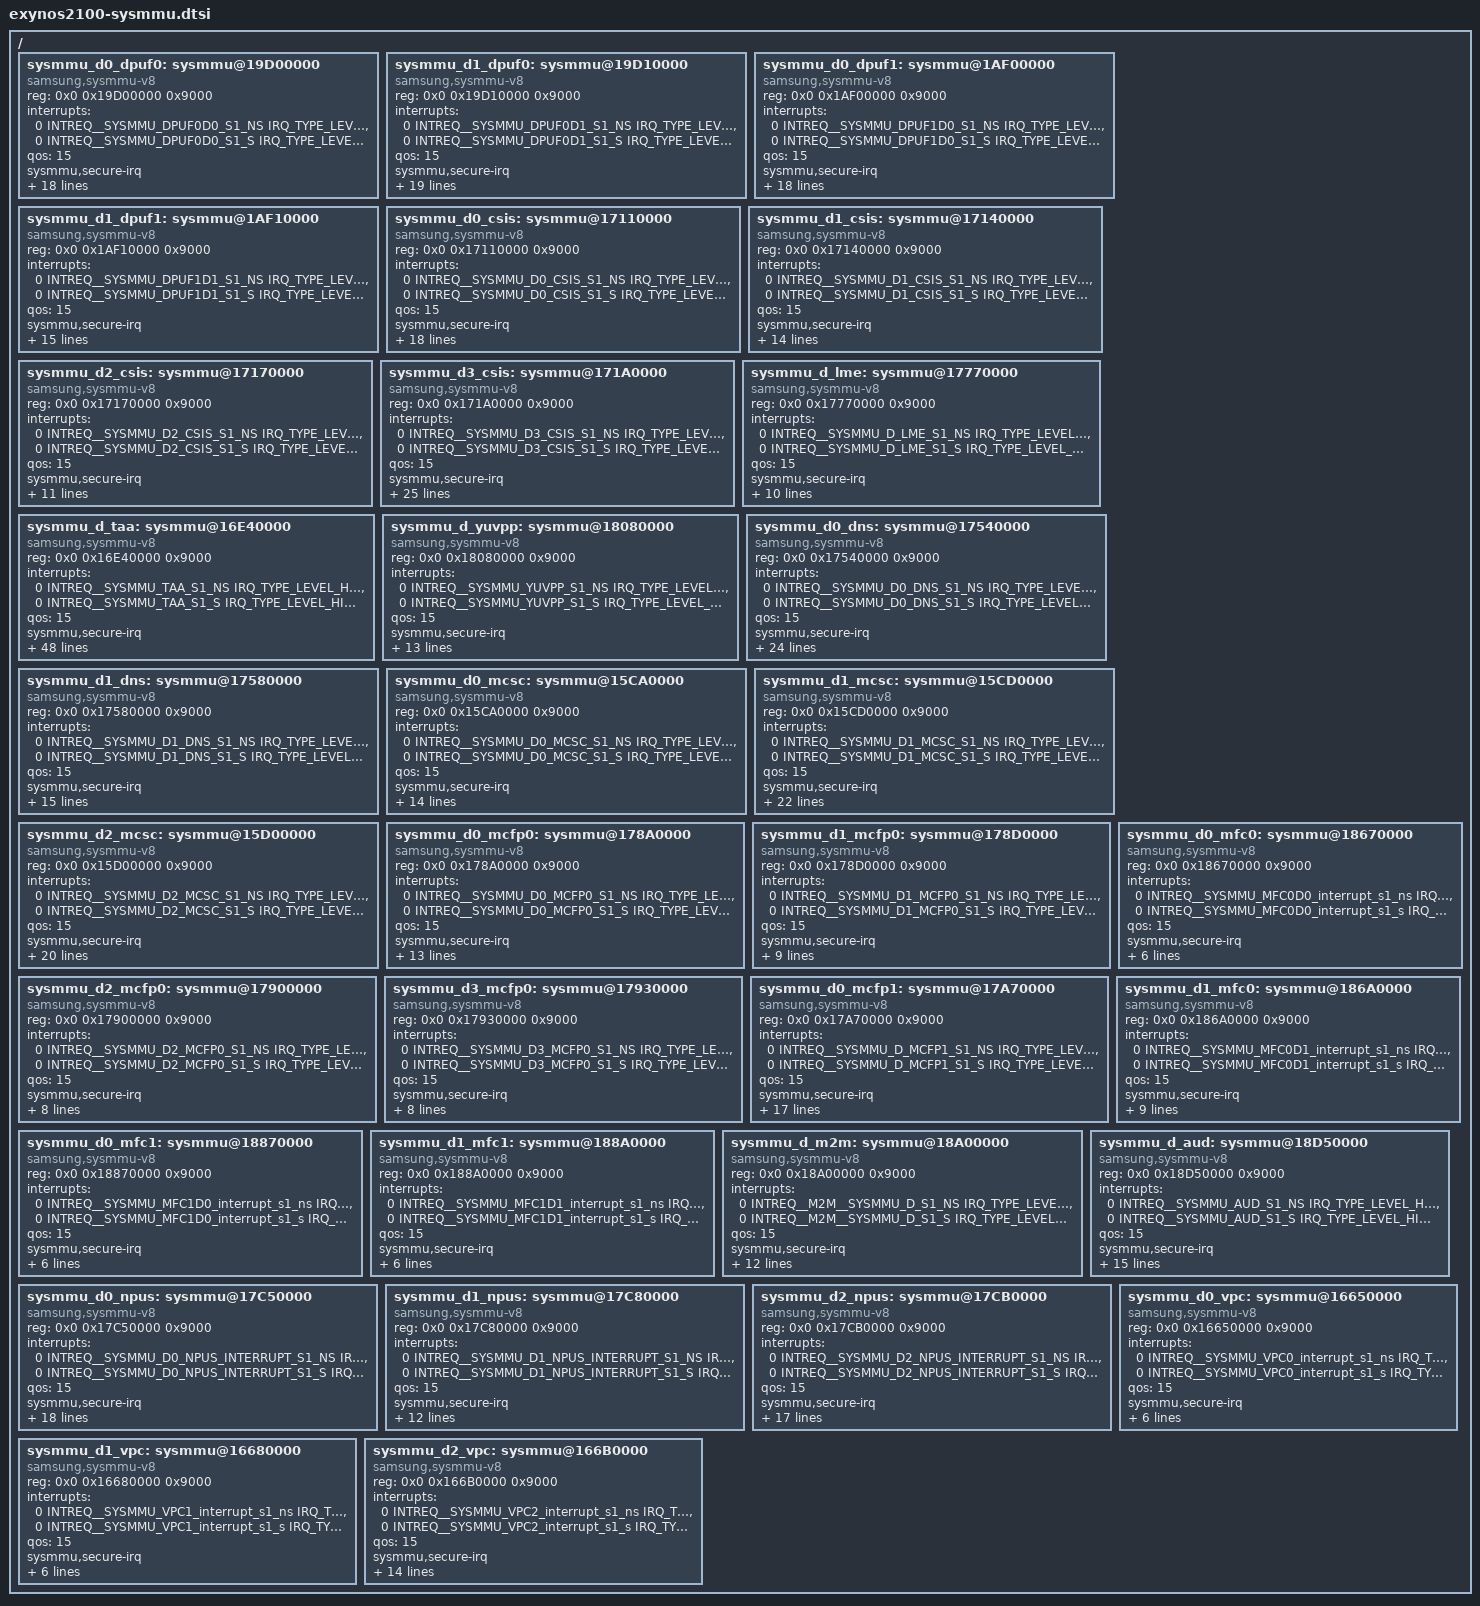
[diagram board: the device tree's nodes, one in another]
/*
 * SAMSUNG EXYNOS2100 SoC device tree source
 *
 * Copyright (c) 2019 Samsung Electronics Co., Ltd.
 *		http://www.samsung.com
 *
 * SAMSUNG EXYNOS2100 SoC device nodes are listed in this file.
 * EXYNOS2100 based board files can include this file and provide
 * values for board specfic bindings.
 *
 * This program is free software; you can redistribute it and/or modify
 * it under the terms of the GNU General Public License version 2 as
 * published by the Free Software Foundation.
 */

#include <dt-bindings/clock/exynos2100.h>
#include <dt-bindings/interrupt-controller/arm-gic.h>
#include <dt-bindings/soc/samsung,sysmmu-v8.h>

/ {
	sysmmu_d0_dpuf0: sysmmu@19D00000 {
		compatible = "samsung,sysmmu-v8";
		reg = <0x0 0x19D00000 0x9000>;
		interrupts = <0 INTREQ__SYSMMU_DPUF0D0_S1_NS IRQ_TYPE_LEVEL_HIGH>,
			     <0 INTREQ__SYSMMU_DPUF0D0_S1_S  IRQ_TYPE_LEVEL_HIGH>;
		qos = <15>;

		sysmmu,secure-irq;
		sysmmu,secure_base = <0x19D30000>;
		sysmmu,default_tlb = <TLB_CFG(BL64, PREFETCH_PREDICTION)>;
		sysmmu,tlb_property =
			<1  TLB_CFG(BL64, PREFETCH_PREDICTION) DIR_READ SYSMMU_ID_MASK(0x5,  0xF)>,
			<2  TLB_CFG(BL16, PREFETCH_PREDICTION) DIR_READ SYSMMU_ID_MASK(0x8,  0xF)>,
			<3  TLB_CFG(BL1,  PREFETCH_PREDICTION) DIR_READ SYSMMU_ID_MASK(0x6,  0xF)>,
			<4  TLB_CFG(BL1,  PREFETCH_PREDICTION) DIR_READ SYSMMU_ID_MASK(0xA,  0xF)>,
			<5  TLB_CFG(BL1,  PREFETCH_PREDICTION) DIR_READ SYSMMU_ID_MASK(0xC,  0xF)>,
			<6  TLB_CFG(BL1,  PREFETCH_PREDICTION) DIR_READ SYSMMU_ID_MASK(0x1E, 0x1F)>,
			<7  TLB_CFG(BL1,  PREFETCH_PREDICTION) DIR_READ SYSMMU_ID_MASK(0x0,  0xF)>,
			<8  TLB_CFG(BL1,  PREFETCH_PREDICTION) DIR_READ SYSMMU_ID_MASK(0x7,  0xF)>,
			<9  TLB_CFG(BL1,  PREFETCH_PREDICTION) DIR_READ SYSMMU_ID_MASK(0xD,  0xF)>,
			<10 TLB_CFG(BL1,  PREFETCH_PREDICTION) DIR_READ SYSMMU_ID_MASK(0xE,  0x1F)>,
			<11 TLB_CFG(BL1,  PREFETCH_PREDICTION) DIR_READ SYSMMU_ID_MASK(0xF,  0x1F)>;
		port-name = "DPUF0 D0";
		#iommu-cells = <0>;
		clocks = <&clock GATE_SYSMMU_DPUF0D0_QCH_S1>;
		clock-names = "aclk";
		power-domains = <&pd_dpuf0>;
	};

	sysmmu_d1_dpuf0: sysmmu@19D10000 {
		compatible = "samsung,sysmmu-v8";
		reg = <0x0 0x19D10000 0x9000>;
		interrupts = <0 INTREQ__SYSMMU_DPUF0D1_S1_NS IRQ_TYPE_LEVEL_HIGH>,
			     <0 INTREQ__SYSMMU_DPUF0D1_S1_S  IRQ_TYPE_LEVEL_HIGH>;
		qos = <15>;

		sysmmu,secure-irq;
		sysmmu,secure_base = <0x19D40000>;
		sysmmu,default_tlb = <TLB_CFG(BL16, PREFETCH_PREDICTION)>;
		sysmmu,tlb_property =
			<1  TLB_CFG(BL16, PREFETCH_PREDICTION) DIR_READ  SYSMMU_ID_MASK(0xC,  0xF)>,
			<2  TLB_CFG(BL1,  PREFETCH_PREDICTION) DIR_READ  SYSMMU_ID_MASK(0xD,  0xF)>,
			<3  TLB_CFG(BL1,  PREFETCH_PREDICTION) DIR_READ  SYSMMU_ID_MASK(0x2,  0xF)>,
			<4  TLB_CFG(BL1,  PREFETCH_PREDICTION) DIR_READ  SYSMMU_ID_MASK(0x4,  0xF)>,
			<5  TLB_CFG(BL1,  PREFETCH_PREDICTION) DIR_READ  SYSMMU_ID_MASK(0xE,  0x1F)>,
			<6  TLB_CFG(BL1,  PREFETCH_PREDICTION) DIR_READ  SYSMMU_ID_MASK(0x1E, 0x1F)>,
			<7  TLB_CFG(BL1,  PREFETCH_PREDICTION) DIR_READ  SYSMMU_ID_MASK(0x5,  0xF)>,
			<8  TLB_CFG(BL1,  PREFETCH_PREDICTION) DIR_READ  SYSMMU_ID_MASK(0x8,  0xF)>,
			<9  TLB_CFG(BL1,  PREFETCH_PREDICTION) DIR_READ  SYSMMU_ID_MASK(0xF,  0x1F)>,
			<10 TLB_CFG(BL1,  PREFETCH_PREDICTION) DIR_WRITE SYSMMU_ID_MASK(0x0,  0xF)>,
			<11 TLB_CFG(BL1,  PREFETCH_PREDICTION) DIR_WRITE SYSMMU_ID_MASK(0x1,  0xF)>,
			<12 TLB_CFG(BL1,  PREFETCH_NONE)       DIR_WRITE SYSMMU_ID_MASK(0x8,  0xF)>;
		port-name = "DPUF0 D1";
		#iommu-cells = <0>;
		clocks = <&clock GATE_SYSMMU_DPUF0D1_QCH_S1>;
		clock-names = "aclk";
		power-domains = <&pd_dpuf0>;
	};

	sysmmu_d0_dpuf1: sysmmu@1AF00000 {
		compatible = "samsung,sysmmu-v8";
		reg = <0x0 0x1AF00000 0x9000>;
		interrupts = <0 INTREQ__SYSMMU_DPUF1D0_S1_NS IRQ_TYPE_LEVEL_HIGH>,
			     <0 INTREQ__SYSMMU_DPUF1D0_S1_S  IRQ_TYPE_LEVEL_HIGH>;
		qos = <15>;

		sysmmu,secure-irq;
		sysmmu,secure_base = <0x1AF30000>;
		sysmmu,default_tlb = <TLB_CFG(BL64, PREFETCH_PREDICTION)>;
		sysmmu,tlb_property =
			<1  TLB_CFG(BL64, PREFETCH_PREDICTION) DIR_READ SYSMMU_ID_MASK(0x5,  0xF)>,
			<2  TLB_CFG(BL16, PREFETCH_PREDICTION) DIR_READ SYSMMU_ID_MASK(0x8,  0xF)>,
			<3  TLB_CFG(BL1,  PREFETCH_PREDICTION) DIR_READ SYSMMU_ID_MASK(0x6,  0xF)>,
			<4  TLB_CFG(BL1,  PREFETCH_PREDICTION) DIR_READ SYSMMU_ID_MASK(0xA,  0xF)>,
			<5  TLB_CFG(BL1,  PREFETCH_PREDICTION) DIR_READ SYSMMU_ID_MASK(0xC,  0xF)>,
			<6  TLB_CFG(BL1,  PREFETCH_PREDICTION) DIR_READ SYSMMU_ID_MASK(0x1E, 0x1F)>,
			<7  TLB_CFG(BL1,  PREFETCH_PREDICTION) DIR_READ SYSMMU_ID_MASK(0x0,  0xF)>,
			<8  TLB_CFG(BL1,  PREFETCH_PREDICTION) DIR_READ SYSMMU_ID_MASK(0x7,  0xF)>,
			<9  TLB_CFG(BL1,  PREFETCH_PREDICTION) DIR_READ SYSMMU_ID_MASK(0xD,  0xF)>,
			<10 TLB_CFG(BL1,  PREFETCH_PREDICTION) DIR_READ SYSMMU_ID_MASK(0xE,  0x1F)>,
			<11 TLB_CFG(BL1,  PREFETCH_PREDICTION) DIR_READ SYSMMU_ID_MASK(0xF,  0x1F)>;
		port-name = "DPUF1 D0";
		#iommu-cells = <0>;
		clocks = <&clock GATE_SYSMMU_DPUF1D0_QCH_S1>;
		clock-names = "aclk";
		power-domains = <&pd_dpuf1>;
	};

	sysmmu_d1_dpuf1: sysmmu@1AF10000 {
		compatible = "samsung,sysmmu-v8";
		reg = <0x0 0x1AF10000 0x9000>;
		interrupts = <0 INTREQ__SYSMMU_DPUF1D1_S1_NS IRQ_TYPE_LEVEL_HIGH>,
			     <0 INTREQ__SYSMMU_DPUF1D1_S1_S  IRQ_TYPE_LEVEL_HIGH>;
		qos = <15>;

		sysmmu,secure-irq;
		sysmmu,secure_base = <0x1AF40000>;
		sysmmu,default_tlb = <TLB_CFG(BL16, PREFETCH_PREDICTION)>;
		sysmmu,tlb_property =
			<1  TLB_CFG(BL16, PREFETCH_PREDICTION) DIR_READ SYSMMU_ID_MASK(0xC, 0xF)>,
			<3  TLB_CFG(BL1,  PREFETCH_PREDICTION) DIR_READ SYSMMU_ID_MASK(0x2, 0xF)>,
			<4  TLB_CFG(BL1,  PREFETCH_PREDICTION) DIR_READ SYSMMU_ID_MASK(0x4, 0xF)>,
			<5  TLB_CFG(BL1,  PREFETCH_PREDICTION) DIR_READ SYSMMU_ID_MASK(0xE, 0x1F)>,
			<6  TLB_CFG(BL1,  PREFETCH_PREDICTION) DIR_READ SYSMMU_ID_MASK(0x5, 0xF)>,
			<7  TLB_CFG(BL1,  PREFETCH_PREDICTION) DIR_READ SYSMMU_ID_MASK(0x8, 0xF)>,
			<8  TLB_CFG(BL1,  PREFETCH_PREDICTION) DIR_READ SYSMMU_ID_MASK(0xD, 0xF)>,
			<9  TLB_CFG(BL1,  PREFETCH_PREDICTION) DIR_READ SYSMMU_ID_MASK(0xF, 0x1F)>;
		port-name = "DPUF1 D1";
		#iommu-cells = <0>;
		clocks = <&clock GATE_SYSMMU_DPUF1D1_QCH_S1>;
		clock-names = "aclk";
		power-domains = <&pd_dpuf1>;
	};

	sysmmu_d0_csis: sysmmu@17110000 {
		compatible = "samsung,sysmmu-v8";
		reg = <0x0 0x17110000 0x9000>;
		interrupts = <0 INTREQ__SYSMMU_D0_CSIS_S1_NS IRQ_TYPE_LEVEL_HIGH>,
			     <0 INTREQ__SYSMMU_D0_CSIS_S1_S  IRQ_TYPE_LEVEL_HIGH>;
		qos = <15>;

		sysmmu,secure-irq;
		sysmmu,secure_base = <0x17100000>;
		sysmmu,default_tlb = <TLB_CFG(BL1, PREFETCH_PREDICTION)>;
		sysmmu,tlb_property =
			<1  TLB_CFG(BL1, PREFETCH_PREDICTION) DIR_WRITE SYSMMU_ID_MASK(0x2, 0xF)>,
			<2  TLB_CFG(BL1, PREFETCH_PREDICTION) DIR_WRITE SYSMMU_ID_MASK(0x4, 0xF)>,
			<3  TLB_CFG(BL1, PREFETCH_PREDICTION) DIR_WRITE SYSMMU_ID_MASK(0x6, 0xF)>,
			<4  TLB_CFG(BL1, PREFETCH_PREDICTION) DIR_WRITE SYSMMU_ID_MASK(0x8, 0xF)>,
			<5  TLB_CFG(BL1, PREFETCH_PREDICTION) DIR_WRITE SYSMMU_ID_MASK(0xA, 0xF)>,
			<6  TLB_CFG(BL1, PREFETCH_PREDICTION) DIR_WRITE SYSMMU_ID_MASK(0xC, 0xF)>,
			<7  TLB_CFG(BL1, PREFETCH_PREDICTION) DIR_WRITE SYSMMU_ID_MASK(0xE, 0xF)>,
			<8  TLB_CFG(BL1, PREFETCH_PREDICTION) DIR_WRITE SYSMMU_ID_MASK(0x1, 0xF)>,
			<9  TLB_CFG(BL1, PREFETCH_PREDICTION) DIR_WRITE SYSMMU_ID_MASK(0x5, 0xF)>,
			<10 TLB_CFG(BL1, PREFETCH_PREDICTION) DIR_WRITE SYSMMU_ID_MASK(0x9, 0xF)>,
			<11 TLB_CFG(BL1, PREFETCH_PREDICTION) DIR_WRITE SYSMMU_ID_MASK(0xD, 0xF)>;
		port-name = "CSIS DMA0,1";
		#iommu-cells = <0>;
		clocks = <&clock INTREQ__SYSMMU_D0_CSIS_S1_S>;
		clock-names = "aclk";
		power-domains = <&pd_csis>;
	};

	sysmmu_d1_csis: sysmmu@17140000 {
		compatible = "samsung,sysmmu-v8";
		reg = <0x0 0x17140000 0x9000>;
		interrupts = <0 INTREQ__SYSMMU_D1_CSIS_S1_NS IRQ_TYPE_LEVEL_HIGH>,
			     <0 INTREQ__SYSMMU_D1_CSIS_S1_S  IRQ_TYPE_LEVEL_HIGH>;
		qos = <15>;

		sysmmu,secure-irq;
		sysmmu,secure_base = <0x17130000>;
		sysmmu,default_tlb = <TLB_CFG(BL1, PREFETCH_PREDICTION)>;
		sysmmu,tlb_property =
			<1 TLB_CFG(BL1, PREFETCH_PREDICTION) DIR_WRITE SYSMMU_ID_MASK(0x4, 0xF)>,
			<2 TLB_CFG(BL1, PREFETCH_PREDICTION) DIR_WRITE SYSMMU_ID_MASK(0x8, 0xF)>,
			<3 TLB_CFG(BL1, PREFETCH_PREDICTION) DIR_WRITE SYSMMU_ID_MASK(0xC, 0xF)>,
			<4 TLB_CFG(BL1, PREFETCH_PREDICTION) DIR_WRITE SYSMMU_ID_MASK(0x1, 0xF)>,
			<5 TLB_CFG(BL1, PREFETCH_PREDICTION) DIR_WRITE SYSMMU_ID_MASK(0x5, 0xF)>,
			<6 TLB_CFG(BL1, PREFETCH_PREDICTION) DIR_WRITE SYSMMU_ID_MASK(0x9, 0xF)>,
			<7 TLB_CFG(BL1, PREFETCH_PREDICTION) DIR_WRITE SYSMMU_ID_MASK(0xD, 0xF)>;
		port-name = "CSIS DMA2,3";
		#iommu-cells = <0>;
		clocks = <&clock INTREQ__SYSMMU_D1_CSIS_S1_S>;
		clock-names = "aclk";
		power-domains = <&pd_csis>;
	};

	sysmmu_d2_csis: sysmmu@17170000 {
		compatible = "samsung,sysmmu-v8";
		reg = <0x0 0x17170000 0x9000>;
		interrupts = <0 INTREQ__SYSMMU_D2_CSIS_S1_NS IRQ_TYPE_LEVEL_HIGH>,
			     <0 INTREQ__SYSMMU_D2_CSIS_S1_S  IRQ_TYPE_LEVEL_HIGH>;
		qos = <15>;

		sysmmu,secure-irq;
		sysmmu,secure_base = <0x17160000>;
		sysmmu,default_tlb = <TLB_CFG(BL1, PREFETCH_PREDICTION)>;
		sysmmu,tlb_property =
			<1 TLB_CFG(BL1, PREFETCH_PREDICTION) DIR_WRITE SYSMMU_ID_MASK(0x4, 0x7)>,
			<2 TLB_CFG(BL1, PREFETCH_PREDICTION) DIR_WRITE SYSMMU_ID_MASK(0x1, 0x7)>,
			<3 TLB_CFG(BL1, PREFETCH_PREDICTION) DIR_WRITE SYSMMU_ID_MASK(0x2, 0x7)>,
			<4 TLB_CFG(BL1, PREFETCH_PREDICTION) DIR_WRITE SYSMMU_ID_MASK(0x3, 0x7)>;
		port-name = "CSIS ZSL0";
		#iommu-cells = <0>;
		clocks = <&clock INTREQ__SYSMMU_D2_CSIS_S1_S>;
		clock-names = "aclk";
		power-domains = <&pd_csis>;
	};

	sysmmu_d3_csis: sysmmu@171A0000 {
		compatible = "samsung,sysmmu-v8";
		reg = <0x0 0x171A0000 0x9000>;
		interrupts = <0 INTREQ__SYSMMU_D3_CSIS_S1_NS IRQ_TYPE_LEVEL_HIGH>,
			     <0 INTREQ__SYSMMU_D3_CSIS_S1_S  IRQ_TYPE_LEVEL_HIGH>;
		qos = <15>;

		sysmmu,secure-irq;
		sysmmu,secure_base = <0x17190000>;
		sysmmu,default_tlb = <TLB_CFG(BL1, PREFETCH_PREDICTION)>;
		sysmmu,tlb_property =
			<1  TLB_CFG(BL1, PREFETCH_PREDICTION) DIR_WRITE SYSMMU_ID_MASK(0x40, 0x7F)>,
			<2  TLB_CFG(BL1, PREFETCH_PREDICTION) DIR_WRITE SYSMMU_ID_MASK(0x8,  0x7F)>,
			<3  TLB_CFG(BL1, PREFETCH_PREDICTION) DIR_WRITE SYSMMU_ID_MASK(0x10, 0x7F)>,
			<4  TLB_CFG(BL1, PREFETCH_PREDICTION) DIR_WRITE SYSMMU_ID_MASK(0x18, 0x7F)>,
			<5  TLB_CFG(BL1, PREFETCH_PREDICTION) DIR_WRITE SYSMMU_ID_MASK(0x1,  0xF)>,
			<6  TLB_CFG(BL1, PREFETCH_PREDICTION) DIR_READ  SYSMMU_ID_MASK(0x1,  0xF)>,
			<7  TLB_CFG(BL1, PREFETCH_PREDICTION) DIR_READ  SYSMMU_ID_MASK(0x9,  0xF)>,
			<8  TLB_CFG(BL1, PREFETCH_PREDICTION) DIR_WRITE SYSMMU_ID_MASK(0x2,  0xF)>,
			<9  TLB_CFG(BL1, PREFETCH_PREDICTION) DIR_READ  SYSMMU_ID_MASK(0x2,  0xF)>,
			<10 TLB_CFG(BL1, PREFETCH_PREDICTION) DIR_WRITE SYSMMU_ID_MASK(0x3,  0xF)>,
			<11 TLB_CFG(BL1, PREFETCH_PREDICTION) DIR_READ  SYSMMU_ID_MASK(0x3,  0xF)>,
			<12 TLB_CFG(BL1, PREFETCH_PREDICTION) DIR_WRITE SYSMMU_ID_MASK(0x4,  0xF)>,
			<13 TLB_CFG(BL1, PREFETCH_PREDICTION) DIR_READ  SYSMMU_ID_MASK(0x4,  0xF)>,
			<14 TLB_CFG(BL1, PREFETCH_PREDICTION) DIR_READ  SYSMMU_ID_MASK(0x5,  0xF)>,
			<15 TLB_CFG(BL1, PREFETCH_PREDICTION) DIR_READ  SYSMMU_ID_MASK(0x6,  0xF)>,
			<16 TLB_CFG(BL1, PREFETCH_PREDICTION) DIR_WRITE SYSMMU_ID_MASK(0x20, 0x7F)>,
			<17 TLB_CFG(BL1, PREFETCH_NONE)       DIR_WRITE SYSMMU_ID_MASK(0x28, 0x7F)>,
			<18 TLB_CFG(BL1, PREFETCH_NONE)       DIR_WRITE SYSMMU_ID_MASK(0x7,  0xF)>;
		port-name = "CSIS STRP,PDP";
		#iommu-cells = <0>;
		clocks = <&clock INTREQ__SYSMMU_D3_CSIS_S1_S>;
		clock-names = "aclk";
		power-domains = <&pd_csis>;
	};

	sysmmu_d_lme: sysmmu@17770000 {
		compatible = "samsung,sysmmu-v8";
		reg = <0x0 0x17770000 0x9000>;
		interrupts = <0 INTREQ__SYSMMU_D_LME_S1_NS IRQ_TYPE_LEVEL_HIGH>,
			     <0 INTREQ__SYSMMU_D_LME_S1_S  IRQ_TYPE_LEVEL_HIGH>;
		qos = <15>;

		sysmmu,secure-irq;
		sysmmu,secure_base = <0x17780000>;
		sysmmu,default_tlb = <TLB_CFG(BL2, PREFETCH_NONE)>;
		sysmmu,tlb_property =
			<1 TLB_CFG(BL1, PREFETCH_PREDICTION) DIR_WRITE SYSMMU_ID_MASK(0x0, 0x7)>,
			<2 TLB_CFG(BL1, PREFETCH_PREDICTION) DIR_WRITE SYSMMU_ID_MASK(0x2, 0x7)>,
			<3 TLB_CFG(BL1, PREFETCH_NONE)       DIR_WRITE SYSMMU_ID_MASK(0x3, 0x7)>;
		port-name = "LME";
		#iommu-cells = <0>;
		clocks = <&clock GATE_SYSMMU_D_LME_QCH_S1>;
		clock-names = "aclk";
		power-domains = <&pd_lme>;
	};

	sysmmu_d_taa: sysmmu@16E40000 {
		compatible = "samsung,sysmmu-v8";
		reg = <0x0 0x16E40000 0x9000>;
		interrupts = <0 INTREQ__SYSMMU_TAA_S1_NS IRQ_TYPE_LEVEL_HIGH>,
			     <0 INTREQ__SYSMMU_TAA_S1_S  IRQ_TYPE_LEVEL_HIGH>;
		qos = <15>;

		sysmmu,secure-irq;
		sysmmu,secure_base = <0x16E30000>;
		sysmmu,default_tlb = <TLB_CFG(BL1, PREFETCH_PREDICTION)>;
		sysmmu,tlb_property =
			<1  TLB_CFG(BL1, PREFETCH_PREDICTION) DIR_WRITE SYSMMU_ID_MASK(0x80,  0x1FF)>,
			<2  TLB_CFG(BL1, PREFETCH_PREDICTION) DIR_WRITE SYSMMU_ID_MASK(0x100, 0x1FF)>,
			<3  TLB_CFG(BL1, PREFETCH_PREDICTION) DIR_WRITE SYSMMU_ID_MASK(0x180, 0x1FF)>,
			<4  TLB_CFG(BL1, PREFETCH_PREDICTION) DIR_WRITE SYSMMU_ID_MASK(0x1,   0x1FF)>,
			<5  TLB_CFG(BL1, PREFETCH_PREDICTION) DIR_WRITE SYSMMU_ID_MASK(0x81,  0x1FF)>,
			<6  TLB_CFG(BL1, PREFETCH_PREDICTION) DIR_WRITE SYSMMU_ID_MASK(0x101, 0x1FF)>,
			<7  TLB_CFG(BL1, PREFETCH_PREDICTION) DIR_WRITE SYSMMU_ID_MASK(0x181, 0x1FF)>,
			<8  TLB_CFG(BL1, PREFETCH_PREDICTION) DIR_WRITE SYSMMU_ID_MASK(0x2,   0x1FF)>,
			<9  TLB_CFG(BL1, PREFETCH_PREDICTION) DIR_WRITE SYSMMU_ID_MASK(0x22,  0x1FF)>,
			<10 TLB_CFG(BL1, PREFETCH_PREDICTION) DIR_WRITE SYSMMU_ID_MASK(0x42,  0x1FF)>,
			<11 TLB_CFG(BL1, PREFETCH_PREDICTION) DIR_WRITE SYSMMU_ID_MASK(0x82,  0x1FF)>,
			<12 TLB_CFG(BL1, PREFETCH_PREDICTION) DIR_WRITE SYSMMU_ID_MASK(0xA2,  0x1FF)>,
			<13 TLB_CFG(BL1, PREFETCH_PREDICTION) DIR_WRITE SYSMMU_ID_MASK(0xC2,  0x1FF)>,
			<14 TLB_CFG(BL1, PREFETCH_PREDICTION) DIR_WRITE SYSMMU_ID_MASK(0x102, 0x1FF)>,
			<15 TLB_CFG(BL1, PREFETCH_PREDICTION) DIR_WRITE SYSMMU_ID_MASK(0x122, 0x1FF)>,
			<16 TLB_CFG(BL1, PREFETCH_PREDICTION) DIR_WRITE SYSMMU_ID_MASK(0x142, 0x1FF)>,
			<17 TLB_CFG(BL1, PREFETCH_PREDICTION) DIR_WRITE SYSMMU_ID_MASK(0x182, 0x1FF)>,
			<18 TLB_CFG(BL1, PREFETCH_PREDICTION) DIR_WRITE SYSMMU_ID_MASK(0x1A2, 0x1FF)>,
			<19 TLB_CFG(BL1, PREFETCH_PREDICTION) DIR_WRITE SYSMMU_ID_MASK(0x1C2, 0x1FF)>,
			<20 TLB_CFG(BL1, PREFETCH_PREDICTION) DIR_WRITE SYSMMU_ID_MASK(0x3,   0x1FF)>,
			<21 TLB_CFG(BL1, PREFETCH_PREDICTION) DIR_WRITE SYSMMU_ID_MASK(0x84,  0x1FF)>,
			<22 TLB_CFG(BL1, PREFETCH_PREDICTION) DIR_WRITE SYSMMU_ID_MASK(0x105, 0x1FF)>,
			<23 TLB_CFG(BL1, PREFETCH_PREDICTION) DIR_WRITE SYSMMU_ID_MASK(0x186, 0x1FF)>,
			<24 TLB_CFG(BL1, PREFETCH_PREDICTION) DIR_WRITE SYSMMU_ID_MASK(0x7,   0x1FF)>,
			<25 TLB_CFG(BL1, PREFETCH_PREDICTION) DIR_WRITE SYSMMU_ID_MASK(0x87,  0x1FF)>,
			<26 TLB_CFG(BL1, PREFETCH_PREDICTION) DIR_WRITE SYSMMU_ID_MASK(0x107, 0x1FF)>,
			<27 TLB_CFG(BL1, PREFETCH_PREDICTION) DIR_WRITE SYSMMU_ID_MASK(0x187, 0x1FF)>,
			<28 TLB_CFG(BL1, PREFETCH_PREDICTION) DIR_WRITE SYSMMU_ID_MASK(0x8,   0x1FF)>,
			<29 TLB_CFG(BL1, PREFETCH_PREDICTION) DIR_WRITE SYSMMU_ID_MASK(0x88,  0x1FF)>,
			<30 TLB_CFG(BL1, PREFETCH_PREDICTION) DIR_WRITE SYSMMU_ID_MASK(0x108, 0x1FF)>,
			<31 TLB_CFG(BL1, PREFETCH_PREDICTION) DIR_WRITE SYSMMU_ID_MASK(0x188, 0x1FF)>,
			<32 TLB_CFG(BL1, PREFETCH_PREDICTION) DIR_WRITE SYSMMU_ID_MASK(0x9,   0x1FF)>,
			<33 TLB_CFG(BL1, PREFETCH_PREDICTION) DIR_WRITE SYSMMU_ID_MASK(0x89,  0x1FF)>,
			<34 TLB_CFG(BL1, PREFETCH_PREDICTION) DIR_WRITE SYSMMU_ID_MASK(0x109, 0x1FF)>,
			<35 TLB_CFG(BL1, PREFETCH_PREDICTION) DIR_WRITE SYSMMU_ID_MASK(0x189, 0x1FF)>,
			<36 TLB_CFG(BL1, PREFETCH_PREDICTION) DIR_WRITE SYSMMU_ID_MASK(0xA,   0x1FF)>,
			<37 TLB_CFG(BL1, PREFETCH_PREDICTION) DIR_WRITE SYSMMU_ID_MASK(0x8A,  0x1FF)>,
			<38 TLB_CFG(BL1, PREFETCH_PREDICTION) DIR_WRITE SYSMMU_ID_MASK(0x10A, 0x1FF)>,
			<39 TLB_CFG(BL1, PREFETCH_PREDICTION) DIR_WRITE SYSMMU_ID_MASK(0x18A, 0x1FF)>,
			<40 TLB_CFG(BL1, PREFETCH_NONE)       DIR_WRITE SYSMMU_ID_MASK(0xB,   0x1F)>,
			<41 TLB_CFG(BL1, PREFETCH_NONE)       DIR_WRITE SYSMMU_ID_MASK(0xC,   0x1F)>;
		port-name = "TAA";
		#iommu-cells = <0>;
		clocks = <&clock GATE_SYSMMU_D_TAA_QCH_S1>;
		clock-names = "aclk";
		power-domains = <&pd_taa>;
	};

	sysmmu_d_yuvpp: sysmmu@18080000 {
		compatible = "samsung,sysmmu-v8";
		reg = <0x0 0x18080000 0x9000>;
		interrupts = <0 INTREQ__SYSMMU_YUVPP_S1_NS IRQ_TYPE_LEVEL_HIGH>,
			     <0 INTREQ__SYSMMU_YUVPP_S1_S  IRQ_TYPE_LEVEL_HIGH>;
		qos = <15>;

		sysmmu,secure-irq;
		sysmmu,secure_base = <0x18090000>;
		sysmmu,default_tlb = <TLB_CFG(BL4, PREFETCH_NONE)>;
		sysmmu,tlb_property =
			<1 TLB_CFG(BL4, PREFETCH_NONE)       DIR_WRITE SYSMMU_ID_MASK(0x0, 0x3)>,
			<2 TLB_CFG(BL1, PREFETCH_PREDICTION) DIR_READ  SYSMMU_ID_MASK(0x1, 0x7)>,
			<3 TLB_CFG(BL1, PREFETCH_PREDICTION) DIR_READ  SYSMMU_ID_MASK(0x5, 0x7)>,
			<4 TLB_CFG(BL1, PREFETCH_PREDICTION) DIR_READ  SYSMMU_ID_MASK(0x2, 0x7)>,
			<5 TLB_CFG(BL1, PREFETCH_PREDICTION) DIR_READ  SYSMMU_ID_MASK(0x6, 0x7)>,
			<6 TLB_CFG(BL1, PREFETCH_NONE)       DIR_WRITE SYSMMU_ID_MASK(0x3, 0x7)>;
		port-name = "YUVPP";
		#iommu-cells = <0>;
		clocks = <&clock GATE_SYSMMU_D_YUVPP_QCH_S1>;
		clock-names = "aclk";
		power-domains = <&pd_yuvpp>;
	};

	sysmmu_d0_dns: sysmmu@17540000 {
		compatible = "samsung,sysmmu-v8";
		reg = <0x0 0x17540000 0x9000>;
		interrupts = <0 INTREQ__SYSMMU_D0_DNS_S1_NS IRQ_TYPE_LEVEL_HIGH>,
			     <0 INTREQ__SYSMMU_D0_DNS_S1_S  IRQ_TYPE_LEVEL_HIGH>;
		qos = <15>;

		sysmmu,secure-irq;
		sysmmu,secure_base = <0x17550000>;
		sysmmu,default_tlb = <TLB_CFG(BL1, PREFETCH_PREDICTION)>;
		sysmmu,tlb_property =
			<1  TLB_CFG(BL1, PREFETCH_PREDICTION) DIR_WRITE SYSMMU_ID_MASK(0x0, 0xF)>,
			<2  TLB_CFG(BL1, PREFETCH_PREDICTION) DIR_READ  SYSMMU_ID_MASK(0x1, 0xF)>,
			<3  TLB_CFG(BL1, PREFETCH_PREDICTION) DIR_WRITE SYSMMU_ID_MASK(0x1, 0xF)>,
			<4  TLB_CFG(BL1, PREFETCH_PREDICTION) DIR_READ  SYSMMU_ID_MASK(0x2, 0xF)>,
			<5  TLB_CFG(BL1, PREFETCH_PREDICTION) DIR_WRITE SYSMMU_ID_MASK(0x2, 0xF)>,
			<6  TLB_CFG(BL1, PREFETCH_PREDICTION) DIR_WRITE SYSMMU_ID_MASK(0xA, 0xF)>,
			<7  TLB_CFG(BL1, PREFETCH_PREDICTION) DIR_READ  SYSMMU_ID_MASK(0x3, 0xF)>,
			<8  TLB_CFG(BL1, PREFETCH_PREDICTION) DIR_WRITE SYSMMU_ID_MASK(0x3, 0xF)>,
			<9  TLB_CFG(BL1, PREFETCH_PREDICTION) DIR_READ  SYSMMU_ID_MASK(0x4, 0xF)>,
			<10 TLB_CFG(BL1, PREFETCH_PREDICTION) DIR_WRITE SYSMMU_ID_MASK(0x4, 0xF)>,
			<11 TLB_CFG(BL1, PREFETCH_PREDICTION) DIR_READ  SYSMMU_ID_MASK(0x5, 0xF)>,
			<12 TLB_CFG(BL1, PREFETCH_PREDICTION) DIR_WRITE SYSMMU_ID_MASK(0x5, 0xF)>,
			<13 TLB_CFG(BL1, PREFETCH_PREDICTION) DIR_WRITE SYSMMU_ID_MASK(0xD, 0xF)>,
			<14 TLB_CFG(BL1, PREFETCH_PREDICTION) DIR_READ  SYSMMU_ID_MASK(0x6, 0xF)>,
			<15 TLB_CFG(BL1, PREFETCH_PREDICTION) DIR_WRITE SYSMMU_ID_MASK(0x6, 0xF)>,
			<16 TLB_CFG(BL1, PREFETCH_PREDICTION) DIR_READ  SYSMMU_ID_MASK(0x7, 0xF)>,
			<17 TLB_CFG(BL1, PREFETCH_PREDICTION) DIR_WRITE SYSMMU_ID_MASK(0x7, 0xF)>;
		port-name = "DNS M0-M7";
		#iommu-cells = <0>;
		clocks = <&clock GATE_SYSMMU_D0_DNS_QCH_S1>;
		clock-names = "aclk";
		power-domains = <&pd_dns>;
	};

	sysmmu_d1_dns: sysmmu@17580000 {
		compatible = "samsung,sysmmu-v8";
		reg = <0x0 0x17580000 0x9000>;
		interrupts = <0 INTREQ__SYSMMU_D1_DNS_S1_NS IRQ_TYPE_LEVEL_HIGH>,
			     <0 INTREQ__SYSMMU_D1_DNS_S1_S  IRQ_TYPE_LEVEL_HIGH>;
		qos = <15>;

		sysmmu,secure-irq;
		sysmmu,secure_base = <0x17590000>;
		sysmmu,default_tlb = <TLB_CFG(BL1, PREFETCH_PREDICTION)>;
		sysmmu,tlb_property =
			<1 TLB_CFG(BL1, PREFETCH_PREDICTION) DIR_WRITE SYSMMU_ID_MASK(0x0, 0xF)>,
			<2 TLB_CFG(BL1, PREFETCH_PREDICTION) DIR_WRITE SYSMMU_ID_MASK(0x4, 0xF)>,
			<3 TLB_CFG(BL1, PREFETCH_PREDICTION) DIR_READ  SYSMMU_ID_MASK(0x1, 0xF)>,
			<4 TLB_CFG(BL1, PREFETCH_PREDICTION) DIR_WRITE SYSMMU_ID_MASK(0x1, 0xF)>,
			<5 TLB_CFG(BL1, PREFETCH_PREDICTION) DIR_READ  SYSMMU_ID_MASK(0x2, 0xF)>,
			<6 TLB_CFG(BL1, PREFETCH_PREDICTION) DIR_WRITE SYSMMU_ID_MASK(0x2, 0xF)>,
			<7 TLB_CFG(BL1, PREFETCH_PREDICTION) DIR_WRITE SYSMMU_ID_MASK(0x3, 0xF)>,
			<8 TLB_CFG(BL1, PREFETCH_PREDICTION) DIR_WRITE SYSMMU_ID_MASK(0x4, 0xE)>;
		port-name = "DNS M8-M10";
		#iommu-cells = <0>;
		clocks = <&clock GATE_SYSMMU_D1_DNS_QCH_S1>;
		clock-names = "aclk";
		power-domains = <&pd_dns>;
	};

	sysmmu_d0_mcsc: sysmmu@15CA0000 {
		compatible = "samsung,sysmmu-v8";
		reg = <0x0 0x15CA0000 0x9000>;
		interrupts = <0 INTREQ__SYSMMU_D0_MCSC_S1_NS IRQ_TYPE_LEVEL_HIGH>,
			     <0 INTREQ__SYSMMU_D0_MCSC_S1_S  IRQ_TYPE_LEVEL_HIGH>;
		qos = <15>;

		sysmmu,secure-irq;
		sysmmu,secure_base = <0x15CB0000>;
		sysmmu,default_tlb = <TLB_CFG(BL32, PREFETCH_PREDICTION)>;
		sysmmu,tlb_property =
			<1  TLB_CFG(BL32, PREFETCH_PREDICTION) DIR_READ  SYSMMU_ID_MASK(0x1, 0x7)>,
			<2  TLB_CFG(BL16, PREFETCH_PREDICTION) DIR_WRITE SYSMMU_ID_MASK(0x0, 0xF)>,
			<3  TLB_CFG(BL16, PREFETCH_PREDICTION) DIR_WRITE SYSMMU_ID_MASK(0x8, 0xF)>,
			<4  TLB_CFG(BL1,  PREFETCH_PREDICTION) DIR_WRITE SYSMMU_ID_MASK(0x4, 0xF)>,
			<5  TLB_CFG(BL1,  PREFETCH_PREDICTION) DIR_WRITE SYSMMU_ID_MASK(0xC, 0xF)>,
			<6  TLB_CFG(BL1,  PREFETCH_NONE)       DIR_WRITE SYSMMU_ID_MASK(0x2, 0x7)>,
			<7  TLB_CFG(BL1,  PREFETCH_NONE)       DIR_WRITE SYSMMU_ID_MASK(0x3, 0x7)>;
		port-name = "GDC0 M0, M3";
		#iommu-cells = <0>;
		clocks = <&clock GATE_SYSMMU_D0_MCSC_QCH_S1>;
		clock-names = "aclk";
		power-domains = <&pd_mcsc>;
	};

	sysmmu_d1_mcsc: sysmmu@15CD0000 {
		compatible = "samsung,sysmmu-v8";
		reg = <0x0 0x15CD0000 0x9000>;
		interrupts = <0 INTREQ__SYSMMU_D1_MCSC_S1_NS IRQ_TYPE_LEVEL_HIGH>,
			     <0 INTREQ__SYSMMU_D1_MCSC_S1_S  IRQ_TYPE_LEVEL_HIGH>;
		qos = <15>;

		sysmmu,secure-irq;
		sysmmu,secure_base = <0x15CE0000>;
		sysmmu,default_tlb = <TLB_CFG(BL1, PREFETCH_PREDICTION)>;
		sysmmu,tlb_property =
			<1  TLB_CFG(BL1, PREFETCH_PREDICTION) DIR_WRITE SYSMMU_ID_MASK(0x0,  0x1F)>,
			<2  TLB_CFG(BL1, PREFETCH_PREDICTION) DIR_WRITE SYSMMU_ID_MASK(0x8,  0x1F)>,
			<3  TLB_CFG(BL1, PREFETCH_PREDICTION) DIR_WRITE SYSMMU_ID_MASK(0x10, 0x1F)>,
			<4  TLB_CFG(BL1, PREFETCH_PREDICTION) DIR_WRITE SYSMMU_ID_MASK(0x1,  0x1F)>,
			<5  TLB_CFG(BL1, PREFETCH_PREDICTION) DIR_WRITE SYSMMU_ID_MASK(0x9,  0x1F)>,
			<6  TLB_CFG(BL1, PREFETCH_PREDICTION) DIR_WRITE SYSMMU_ID_MASK(0x11, 0x1F)>,
			<7  TLB_CFG(BL1, PREFETCH_PREDICTION) DIR_READ  SYSMMU_ID_MASK(0x2,  0x7F)>,
			<8  TLB_CFG(BL1, PREFETCH_PREDICTION) DIR_READ  SYSMMU_ID_MASK(0x6,  0x7F)>,
			<9  TLB_CFG(BL1, PREFETCH_PREDICTION) DIR_READ  SYSMMU_ID_MASK(0xA,  0x7F)>,
			<10 TLB_CFG(BL1, PREFETCH_PREDICTION) DIR_READ  SYSMMU_ID_MASK(0xE,  0x7F)>,
			<11 TLB_CFG(BL1, PREFETCH_PREDICTION) DIR_READ  SYSMMU_ID_MASK(0x12, 0x7F)>,
			<12 TLB_CFG(BL1, PREFETCH_PREDICTION) DIR_READ  SYSMMU_ID_MASK(0x16, 0x7F)>,
			<13 TLB_CFG(BL1, PREFETCH_PREDICTION) DIR_READ  SYSMMU_ID_MASK(0x1A, 0x7F)>,
			<14 TLB_CFG(BL1, PREFETCH_PREDICTION) DIR_READ  SYSMMU_ID_MASK(0x5A, 0x7F)>,
			<15 TLB_CFG(BL1, PREFETCH_PREDICTION) DIR_READ  SYSMMU_ID_MASK(0x1E, 0x7F)>;
		port-name = "GDC1 M0, MCSC M4";
		#iommu-cells = <0>;
		clocks = <&clock GATE_SYSMMU_D1_MCSC_QCH_S1>;
		clock-names = "aclk";
		power-domains = <&pd_mcsc>;
	};

	sysmmu_d2_mcsc: sysmmu@15D00000 {
		compatible = "samsung,sysmmu-v8";
		reg = <0x0 0x15D00000 0x9000>;
		interrupts = <0 INTREQ__SYSMMU_D2_MCSC_S1_NS IRQ_TYPE_LEVEL_HIGH>,
			     <0 INTREQ__SYSMMU_D2_MCSC_S1_S  IRQ_TYPE_LEVEL_HIGH>;
		qos = <15>;

		sysmmu,secure-irq;
		sysmmu,secure_base = <0x15D10000>;
		sysmmu,tlb_property =
			<2  TLB_CFG(BL1, PREFETCH_PREDICTION) DIR_WRITE SYSMMU_ID_MASK(0x0,  0x3F)>,
			<3  TLB_CFG(BL1, PREFETCH_PREDICTION) DIR_WRITE SYSMMU_ID_MASK(0x8,  0x3F)>,
			<4  TLB_CFG(BL1, PREFETCH_PREDICTION) DIR_WRITE SYSMMU_ID_MASK(0x10, 0x3F)>,
			<5  TLB_CFG(BL1, PREFETCH_PREDICTION) DIR_WRITE SYSMMU_ID_MASK(0x18, 0x3F)>,
			<6  TLB_CFG(BL1, PREFETCH_PREDICTION) DIR_WRITE SYSMMU_ID_MASK(0x20, 0x3F)>,
			<7  TLB_CFG(BL1, PREFETCH_PREDICTION) DIR_WRITE SYSMMU_ID_MASK(0x1,  0x3F)>,
			<8  TLB_CFG(BL1, PREFETCH_PREDICTION) DIR_WRITE SYSMMU_ID_MASK(0x9,  0x3F)>,
			<9  TLB_CFG(BL1, PREFETCH_PREDICTION) DIR_WRITE SYSMMU_ID_MASK(0x11, 0x3F)>,
			<10 TLB_CFG(BL1, PREFETCH_PREDICTION) DIR_WRITE SYSMMU_ID_MASK(0x19, 0x3F)>,
			<11 TLB_CFG(BL1, PREFETCH_PREDICTION) DIR_WRITE SYSMMU_ID_MASK(0x21, 0x3F)>,
			<12 TLB_CFG(BL1, PREFETCH_PREDICTION) DIR_WRITE SYSMMU_ID_MASK(0x2,  0x3F)>,
			<13 TLB_CFG(BL1, PREFETCH_PREDICTION) DIR_WRITE SYSMMU_ID_MASK(0x12, 0x3F)>,
			<14 TLB_CFG(BL1, PREFETCH_PREDICTION) DIR_WRITE SYSMMU_ID_MASK(0x22, 0x3F)>,
			<15 TLB_CFG(BL1, PREFETCH_NONE)       DIR_WRITE SYSMMU_ID_MASK(0x3,  0xF)>,
			<16 TLB_CFG(BL1, PREFETCH_NONE)       DIR_WRITE SYSMMU_ID_MASK(0x4,  0xF)>;
		port-name = "MCSC M0-M2";
		#iommu-cells = <0>;
		clocks = <&clock GATE_SYSMMU_D2_MCSC_QCH_S1>;
		clock-names = "aclk";
		power-domains = <&pd_mcsc>;
	};

	sysmmu_d0_mcfp0: sysmmu@178A0000 {
		compatible = "samsung,sysmmu-v8";
		reg = <0x0 0x178A0000 0x9000>;
		interrupts = <0 INTREQ__SYSMMU_D0_MCFP0_S1_NS IRQ_TYPE_LEVEL_HIGH>,
			     <0 INTREQ__SYSMMU_D0_MCFP0_S1_S  IRQ_TYPE_LEVEL_HIGH>;
		qos = <15>;

		sysmmu,secure-irq;
		sysmmu,secure_base = <0x178B0000>;
		sysmmu,default_tlb = <TLB_CFG(BL1, PREFETCH_PREDICTION)>;
		sysmmu,tlb_property =
			<1 TLB_CFG(BL1,  PREFETCH_PREDICTION)  DIR_READ  SYSMMU_ID_MASK(0x1, 0x7)>,
			<2 TLB_CFG(BL1,  PREFETCH_PREDICTION)  DIR_READ  SYSMMU_ID_MASK(0x2, 0x7)>,
			<3 TLB_CFG(BL1,  PREFETCH_PREDICTION)  DIR_READ  SYSMMU_ID_MASK(0x4, 0x7)>,
			<4 TLB_CFG(BL1,  PREFETCH_PREDICTION)  DIR_WRITE SYSMMU_ID_MASK(0x0, 0x7)>,
			<5 TLB_CFG(BL1,  PREFETCH_PREDICTION)  DIR_WRITE SYSMMU_ID_MASK(0x4, 0x7)>,
			<6 TLB_CFG(BL16, PREFETCH_PREDICTION)  DIR_READ  SYSMMU_ID_MASK(0x3, 0x7)>;
		port-name = "MCFP0 M0-M3";
		#iommu-cells = <0>;
		clocks = <&clock GATE_SYSMMU_D0_MCFP0_QCH_S1>;
		clock-names = "aclk";
		power-domains = <&pd_mcfp1>;
	};

	sysmmu_d1_mcfp0: sysmmu@178D0000 {
		compatible = "samsung,sysmmu-v8";
		reg = <0x0 0x178D0000 0x9000>;
		interrupts = <0 INTREQ__SYSMMU_D1_MCFP0_S1_NS IRQ_TYPE_LEVEL_HIGH>,
			     <0 INTREQ__SYSMMU_D1_MCFP0_S1_S  IRQ_TYPE_LEVEL_HIGH>;
		qos = <15>;

		sysmmu,secure-irq;
		sysmmu,secure_base = <0x178E0000>;
		sysmmu,default_tlb = <TLB_CFG(BL32, PREFETCH_PREDICTION)>;
		sysmmu,tlb_property =
			<1 TLB_CFG(BL1, PREFETCH_PREDICTION) DIR_READ  SYSMMU_ID_MASK(0x1, 0x1)>,
			<2 TLB_CFG(BL1, PREFETCH_PREDICTION) DIR_WRITE SYSMMU_ID_MASK(0x0, 0x1)>;
		port-name = "MCFP0 M4";
		#iommu-cells = <0>;
		clocks = <&clock GATE_SYSMMU_D1_MCFP0_QCH_S1>;
		clock-names = "aclk";
		power-domains = <&pd_mcfp1>;
	};

	sysmmu_d2_mcfp0: sysmmu@17900000 {
		compatible = "samsung,sysmmu-v8";
		reg = <0x0 0x17900000 0x9000>;
		interrupts = <0 INTREQ__SYSMMU_D2_MCFP0_S1_NS IRQ_TYPE_LEVEL_HIGH>,
			     <0 INTREQ__SYSMMU_D2_MCFP0_S1_S  IRQ_TYPE_LEVEL_HIGH>;
		qos = <15>;

		sysmmu,secure-irq;
		sysmmu,secure_base = <0x17910000>;
		sysmmu,default_tlb = <TLB_CFG(BL32, PREFETCH_PREDICTION)>;
		sysmmu,tlb_property =
			<1 TLB_CFG(BL1, PREFETCH_PREDICTION) DIR_READ SYSMMU_ID_MASK(0x1, 0x1)>;
		port-name = "MCFP0 M5";
		#iommu-cells = <0>;
		clocks = <&clock GATE_SYSMMU_D2_MCFP0_QCH_S1>;
		clock-names = "aclk";
		power-domains = <&pd_mcfp0>;
	};

	sysmmu_d3_mcfp0: sysmmu@17930000 {
		compatible = "samsung,sysmmu-v8";
		reg = <0x0 0x17930000 0x9000>;
		interrupts = <0 INTREQ__SYSMMU_D3_MCFP0_S1_NS IRQ_TYPE_LEVEL_HIGH>,
			     <0 INTREQ__SYSMMU_D3_MCFP0_S1_S  IRQ_TYPE_LEVEL_HIGH>;
		qos = <15>;

		sysmmu,secure-irq;
		sysmmu,secure_base = <0x17940000>;
		sysmmu,default_tlb = <TLB_CFG(BL32, PREFETCH_PREDICTION)>;
		sysmmu,tlb_property =
			<1 TLB_CFG(BL1, PREFETCH_PREDICTION) DIR_READ SYSMMU_ID_MASK(0x1, 0x1)>;
		port-name = "MCFP0 M6";
		#iommu-cells = <0>;
		clocks = <&clock GATE_SYSMMU_D3_MCFP0_QCH_S1>;
		clock-names = "aclk";
		power-domains = <&pd_mcfp0>;
	};

	sysmmu_d0_mcfp1: sysmmu@17A70000 {
		compatible = "samsung,sysmmu-v8";
		reg = <0x0 0x17A70000 0x9000>;
		interrupts = <0 INTREQ__SYSMMU_D_MCFP1_S1_NS IRQ_TYPE_LEVEL_HIGH>,
			     <0 INTREQ__SYSMMU_D_MCFP1_S1_S  IRQ_TYPE_LEVEL_HIGH>;
		qos = <15>;

		sysmmu,secure-irq;
		sysmmu,secure_base = <0x17A80000>;
		sysmmu,default_tlb = <TLB_CFG(BL16, PREFETCH_PREDICTION)>;
		sysmmu,tlb_property =
			<1  TLB_CFG(BL16, PREFETCH_PREDICTION) DIR_READ  SYSMMU_ID_MASK(0x5, 0xF)>,
			<2  TLB_CFG(BL16, PREFETCH_PREDICTION) DIR_READ  SYSMMU_ID_MASK(0x6, 0xF)>,
			<3  TLB_CFG(BL4,  PREFETCH_PREDICTION) DIR_READ  SYSMMU_ID_MASK(0x0, 0xF)>,
			<4  TLB_CFG(BL4,  PREFETCH_PREDICTION) DIR_READ  SYSMMU_ID_MASK(0x4, 0xF)>,
			<5  TLB_CFG(BL4,  PREFETCH_NONE)       DIR_WRITE SYSMMU_ID_MASK(0x0, 0xF)>,
			<6  TLB_CFG(BL4,  PREFETCH_NONE)       DIR_WRITE SYSMMU_ID_MASK(0x4, 0xF)>,
			<7  TLB_CFG(BL1,  PREFETCH_PREDICTION) DIR_WRITE SYSMMU_ID_MASK(0x1, 0xF)>,
			<8  TLB_CFG(BL1,  PREFETCH_PREDICTION) DIR_WRITE SYSMMU_ID_MASK(0x5, 0xF)>,
			<9  TLB_CFG(BL1,  PREFETCH_NONE)       DIR_WRITE SYSMMU_ID_MASK(0x3, 0xF)>,
			<10 TLB_CFG(BL1,  PREFETCH_NONE)       DIR_WRITE SYSMMU_ID_MASK(0x7, 0xF)>;
		port-name = "ORBMCH M0-M2";
		#iommu-cells = <0>;
		clocks = <&clock GATE_SYSMMU_D_MCFP1_QCH_S1>;
		clock-names = "aclk";
		power-domains = <&pd_mcfp1>;
	};

	sysmmu_d0_mfc0: sysmmu@18670000 {
		compatible = "samsung,sysmmu-v8";
		reg = <0x0 0x18670000 0x9000>;
		interrupts = <0 INTREQ__SYSMMU_MFC0D0_interrupt_s1_ns IRQ_TYPE_LEVEL_HIGH>,
			     <0 INTREQ__SYSMMU_MFC0D0_interrupt_s1_s  IRQ_TYPE_LEVEL_HIGH>;
		qos = <15>;

		sysmmu,secure-irq;
		sysmmu,secure_base = <0x18680000>;
		sysmmu,default_tlb = <TLB_CFG(BL8, PREFETCH_NONE)>;
		port-name = "MFC0 D0";
		#iommu-cells = <0>;
		clocks = <&clock GATE_SYSMMU_MFC0D0_QCH_S1>;
		clock-names = "aclk";
		power-domains = <&pd_mfc0>;
	};

	sysmmu_d1_mfc0: sysmmu@186A0000 {
		compatible = "samsung,sysmmu-v8";
		reg = <0x0 0x186A0000 0x9000>;
		interrupts = <0 INTREQ__SYSMMU_MFC0D1_interrupt_s1_ns IRQ_TYPE_LEVEL_HIGH>,
			     <0 INTREQ__SYSMMU_MFC0D1_interrupt_s1_s  IRQ_TYPE_LEVEL_HIGH>;
		qos = <15>;

		sysmmu,secure-irq;
		sysmmu,secure_base = <0x186B0000>;
		sysmmu,default_tlb = <TLB_CFG(BL8, PREFETCH_NONE)>;
		sysmmu,tlb_property =
			<1 TLB_CFG(BL2, PREFETCH_NONE) DIR_RW SYSMMU_ID_MASK(0x1, 0x7)>,
			<2 TLB_CFG(BL1, PREFETCH_NONE) DIR_RW SYSMMU_ID_MASK(0x2, 0x7)>;
		port-name = "MFC0 D1";
		#iommu-cells = <0>;
		clocks = <&clock GATE_SYSMMU_MFC0D1_QCH_S1>;
		clock-names = "aclk";
		power-domains = <&pd_mfc0>;
	};

	sysmmu_d0_mfc1: sysmmu@18870000 {
		compatible = "samsung,sysmmu-v8";
		reg = <0x0 0x18870000 0x9000>;
		interrupts = <0 INTREQ__SYSMMU_MFC1D0_interrupt_s1_ns IRQ_TYPE_LEVEL_HIGH>,
			     <0 INTREQ__SYSMMU_MFC1D0_interrupt_s1_s  IRQ_TYPE_LEVEL_HIGH>;
		qos = <15>;

		sysmmu,secure-irq;
		sysmmu,secure_base = <0x18880000>;
		sysmmu,default_tlb = <TLB_CFG(BL8, PREFETCH_NONE)>;
		port-name = "MFC1 D0";
		#iommu-cells = <0>;
		clocks = <&clock GATE_SYSMMU_MFC1D0_QCH_S1>;
		clock-names = "aclk";
		power-domains = <&pd_mfc1>;
	};

	sysmmu_d1_mfc1: sysmmu@188A0000 {
		compatible = "samsung,sysmmu-v8";
		reg = <0x0 0x188A0000 0x9000>;
		interrupts = <0 INTREQ__SYSMMU_MFC1D1_interrupt_s1_ns IRQ_TYPE_LEVEL_HIGH>,
			     <0 INTREQ__SYSMMU_MFC1D1_interrupt_s1_s  IRQ_TYPE_LEVEL_HIGH>;
		qos = <15>;

		sysmmu,secure-irq;
		sysmmu,secure_base = <0x188B0000>;
		sysmmu,default_tlb = <TLB_CFG(BL8, PREFETCH_NONE)>;
		port-name = "MFC1 D1";
		#iommu-cells = <0>;
		clocks = <&clock GATE_SYSMMU_MFC1D1_QCH_S1>;
		clock-names = "aclk";
		power-domains = <&pd_mfc1>;
	};

	sysmmu_d_m2m: sysmmu@18A00000 {
		compatible = "samsung,sysmmu-v8";
		reg = <0x0 0x18A00000 0x9000>;
		interrupts = <0 INTREQ__M2M__SYSMMU_D_S1_NS IRQ_TYPE_LEVEL_HIGH>,
			     <0 INTREQ__M2M__SYSMMU_D_S1_S  IRQ_TYPE_LEVEL_HIGH>;
		qos = <15>;

		sysmmu,secure-irq;
		sysmmu,secure_base = <0x18A10000>;
		sysmmu,default_tlb = <TLB_CFG(BL32, PREFETCH_NONE)>;
		sysmmu,tlb_property =
			<1 TLB_CFG(BL8, PREFETCH_NONE) DIR_RW    SYSMMU_ID_MASK(0x0, 0x7)>,
			<2 TLB_CFG(BL8, PREFETCH_NONE) DIR_RW    SYSMMU_ID_MASK(0x1, 0x7)>,
			<3 TLB_CFG(BL1, PREFETCH_NONE) DIR_RW    SYSMMU_ID_MASK(0x4, 0x7)>,
			<4 TLB_CFG(BL1, PREFETCH_NONE) DIR_RW    SYSMMU_ID_MASK(0x3, 0x7)>,
			<5 TLB_CFG(BL1, PREFETCH_NONE) DIR_WRITE SYSMMU_ID_MASK(0xA, 0xF)>;
		port-name = "MSCL, SMFC";
		#iommu-cells = <0>;
		clocks = <&clock GATE_SYSMMU_D_M2M_QCH_S1>;
		clock-names = "aclk";
		power-domains = <&pd_m2m>;
	};

	sysmmu_d_aud: sysmmu@18D50000 {
		compatible = "samsung,sysmmu-v8";
		reg = <0x0 0x18D50000 0x9000>;
		interrupts = <0 INTREQ__SYSMMU_AUD_S1_NS IRQ_TYPE_LEVEL_HIGH>,
			     <0 INTREQ__SYSMMU_AUD_S1_S  IRQ_TYPE_LEVEL_HIGH>;
		qos = <15>;

		sysmmu,secure-irq;
		sysmmu,secure_base = <0x18D60000>;
		sysmmu,no-suspend;
		sysmmu,default_tlb = <TLB_CFG(BL1, PREFETCH_NONE)>;
		sysmmu,tlb_property =
			<1 TLB_CFG(BL1, PREFETCH_NONE) DIR_RW SYSMMU_ID_MASK(0x1, 0xF)>,
			<2 TLB_CFG(BL1, PREFETCH_NONE) DIR_RW SYSMMU_ID_MASK(0x9, 0xF)>,
			<3 TLB_CFG(BL1, PREFETCH_NONE) DIR_RW SYSMMU_ID_MASK(0x5, 0x7)>,
			<4 TLB_CFG(BL1, PREFETCH_NONE) DIR_RW SYSMMU_ID_MASK(0x3, 0x7)>,
			<5 TLB_CFG(BL1, PREFETCH_NONE) DIR_RW SYSMMU_ID_MASK(0x4, 0x7)>,
			<6 TLB_CFG(BL1, PREFETCH_NONE) DIR_RW SYSMMU_ID_MASK(0x7, 0xF)>,
			<7 TLB_CFG(BL1, PREFETCH_NONE) DIR_RW SYSMMU_ID_MASK(0xF, 0xF)>;
		port-name = "AUD";
		#iommu-cells = <0>;
		clocks = <&clock GATE_SMMU_AUD_QCH_S1>;
		clock-names = "aclk";
		power-domains = <&pd_aud>;
	};

	sysmmu_d0_npus: sysmmu@17C50000 {
		compatible = "samsung,sysmmu-v8";
		reg = <0x0 0x17C50000 0x9000>;
		interrupts = <0 INTREQ__SYSMMU_D0_NPUS_INTERRUPT_S1_NS IRQ_TYPE_LEVEL_HIGH>,
			     <0 INTREQ__SYSMMU_D0_NPUS_INTERRUPT_S1_S  IRQ_TYPE_LEVEL_HIGH>;
		qos = <15>;

		sysmmu,secure-irq;
		sysmmu,secure_base = <0x17C60000>;
		sysmmu,default_tlb = <TLB_CFG(BL16, PREFETCH_PREDICTION)>;
		sysmmu,tlb_property =
			<1  TLB_CFG(BL16, PREFETCH_PREDICTION) DIR_READ  SYSMMU_ID_MASK(0x0, 0x7)>,
			<2  TLB_CFG(BL16, PREFETCH_PREDICTION) DIR_READ  SYSMMU_ID_MASK(0x4, 0x7)>,
			<3  TLB_CFG(BL16, PREFETCH_PREDICTION) DIR_WRITE SYSMMU_ID_MASK(0x1, 0x3)>,
			<4  TLB_CFG(BL16, PREFETCH_PREDICTION) DIR_READ  SYSMMU_ID_MASK(0x1, 0x7)>,
			<5  TLB_CFG(BL16, PREFETCH_PREDICTION) DIR_READ  SYSMMU_ID_MASK(0x5, 0x7)>,
			<6  TLB_CFG(BL1,  PREFETCH_PREDICTION) DIR_WRITE SYSMMU_ID_MASK(0x2, 0x3)>,
			<7  TLB_CFG(BL1,  PREFETCH_PREDICTION) DIR_READ  SYSMMU_ID_MASK(0x2, 0x7)>,
			<8  TLB_CFG(BL1,  PREFETCH_PREDICTION) DIR_READ  SYSMMU_ID_MASK(0x6, 0x7)>,
			<9  TLB_CFG(BL1,  PREFETCH_PREDICTION) DIR_WRITE SYSMMU_ID_MASK(0x3, 0x3)>,
			<10 TLB_CFG(BL1,  PREFETCH_PREDICTION) DIR_READ  SYSMMU_ID_MASK(0x3, 0x7)>,
			<11 TLB_CFG(BL1,  PREFETCH_PREDICTION) DIR_READ  SYSMMU_ID_MASK(0x7, 0x7)>;
		port-name = "IP NPUS M13";
		#iommu-cells = <0>;
		clocks = <&clock GATE_SYSMMU_D0_NPUS_QCH_S1>;
		clock-names = "aclk";
		power-domains = <&pd_npus>;
	};

	sysmmu_d1_npus: sysmmu@17C80000 {
		compatible = "samsung,sysmmu-v8";
		reg = <0x0 0x17C80000 0x9000>;
		interrupts = <0 INTREQ__SYSMMU_D1_NPUS_INTERRUPT_S1_NS IRQ_TYPE_LEVEL_HIGH>,
			     <0 INTREQ__SYSMMU_D1_NPUS_INTERRUPT_S1_S  IRQ_TYPE_LEVEL_HIGH>;
		qos = <15>;

		sysmmu,secure-irq;
		sysmmu,secure_base = <0x17C90000>;
		sysmmu,default_tlb = <TLB_CFG(BL16, PREFETCH_PREDICTION)>;
		sysmmu,tlb_property =
			<1  TLB_CFG(BL16, PREFETCH_PREDICTION) DIR_READ  SYSMMU_ID_MASK(0x0, 0x7)>,
			<2  TLB_CFG(BL16, PREFETCH_PREDICTION) DIR_READ  SYSMMU_ID_MASK(0x4, 0x7)>,
			<3  TLB_CFG(BL1,  PREFETCH_PREDICTION) DIR_WRITE SYSMMU_ID_MASK(0x2, 0x3)>,
			<4  TLB_CFG(BL1,  PREFETCH_PREDICTION) DIR_READ  SYSMMU_ID_MASK(0x2, 0x7)>,
			<5  TLB_CFG(BL1,  PREFETCH_PREDICTION) DIR_READ  SYSMMU_ID_MASK(0x6, 0x7)>;
		port-name = "IP NPUS M14";
		#iommu-cells = <0>;
		clocks = <&clock GATE_SYSMMU_D1_NPUS_QCH_S1>;
		clock-names = "aclk";
		power-domains = <&pd_npus>;
	};

	sysmmu_d2_npus: sysmmu@17CB0000 {
		compatible = "samsung,sysmmu-v8";
		reg = <0x0 0x17CB0000 0x9000>;
		interrupts = <0 INTREQ__SYSMMU_D2_NPUS_INTERRUPT_S1_NS IRQ_TYPE_LEVEL_HIGH>,
			     <0 INTREQ__SYSMMU_D2_NPUS_INTERRUPT_S1_S  IRQ_TYPE_LEVEL_HIGH>;
		qos = <15>;

		sysmmu,secure-irq;
		sysmmu,secure_base = <0x17CC0000>;
		sysmmu,default_tlb = <TLB_CFG(BL1, PREFETCH_PREDICTION)>;
		sysmmu,tlb_property =
			<1  TLB_CFG(BL1,  PREFETCH_PREDICTION) DIR_READ  SYSMMU_ID_MASK(0x3,  0xF)>,
			<2  TLB_CFG(BL1,  PREFETCH_PREDICTION) DIR_READ  SYSMMU_ID_MASK(0x5,  0xF)>,
			<3  TLB_CFG(BL1,  PREFETCH_PREDICTION) DIR_READ  SYSMMU_ID_MASK(0x7,  0xF)>,
			<4  TLB_CFG(BL1,  PREFETCH_PREDICTION) DIR_RW    SYSMMU_ID_MASK(0x6,  0x37)>,
			<5  TLB_CFG(BL16, PREFETCH_PREDICTION) DIR_RW    SYSMMU_ID_MASK(0x2,  0x37)>,
			<6  TLB_CFG(BL16, PREFETCH_PREDICTION) DIR_RW    SYSMMU_ID_MASK(0x12, 0x37)>,
			<7  TLB_CFG(BL16, PREFETCH_PREDICTION) DIR_RW    SYSMMU_ID_MASK(0x22, 0x37)>,
			<8  TLB_CFG(BL16, PREFETCH_PREDICTION) DIR_RW    SYSMMU_ID_MASK(0x32, 0x37)>,
			<9  TLB_CFG(BL1,  PREFETCH_NONE)       DIR_RW    SYSMMU_ID_MASK(0x4,  0x7)>,
			<10 TLB_CFG(BL1,  PREFETCH_NONE)       DIR_WRITE SYSMMU_ID_MASK(0x9,  0xD)>;
		port-name = "IP NPUS M15";
		#iommu-cells = <0>;
		clocks = <&clock GATE_SYSMMU_D2_NPUS_QCH_S1>;
		clock-names = "aclk";
		power-domains = <&pd_npus>;
	};

	sysmmu_d0_vpc: sysmmu@16650000 {
		compatible = "samsung,sysmmu-v8";
		reg = <0x0 0x16650000 0x9000>;
		interrupts = <0 INTREQ__SYSMMU_VPC0_interrupt_s1_ns IRQ_TYPE_LEVEL_HIGH>,
			     <0 INTREQ__SYSMMU_VPC0_interrupt_s1_s  IRQ_TYPE_LEVEL_HIGH>;
		qos = <15>;

		sysmmu,secure-irq;
		sysmmu,secure_base = <0x16660000>;
		sysmmu,default_tlb = <TLB_CFG(BL8, PREFETCH_NONE)>;
		port-name = "VPC M0";
		#iommu-cells = <0>;
		clocks = <&clock GATE_SYSMMU_VPC0_QCH_S1>;
		clock-names = "aclk";
		power-domains = <&pd_vpc>;
	};

	sysmmu_d1_vpc: sysmmu@16680000 {
		compatible = "samsung,sysmmu-v8";
		reg = <0x0 0x16680000 0x9000>;
		interrupts = <0 INTREQ__SYSMMU_VPC1_interrupt_s1_ns IRQ_TYPE_LEVEL_HIGH>,
			     <0 INTREQ__SYSMMU_VPC1_interrupt_s1_s  IRQ_TYPE_LEVEL_HIGH>;
		qos = <15>;

		sysmmu,secure-irq;
		sysmmu,secure_base = <0x16690000>;
		sysmmu,default_tlb = <TLB_CFG(BL8, PREFETCH_NONE)>;
		port-name = "VPC M1";
		#iommu-cells = <0>;
		clocks = <&clock GATE_SYSMMU_VPC1_QCH_S1>;
		clock-names = "aclk";
		power-domains = <&pd_vpc>;
	};

	sysmmu_d2_vpc: sysmmu@166B0000 {
		compatible = "samsung,sysmmu-v8";
		reg = <0x0 0x166B0000 0x9000>;
		interrupts = <0 INTREQ__SYSMMU_VPC2_interrupt_s1_ns IRQ_TYPE_LEVEL_HIGH>,
			     <0 INTREQ__SYSMMU_VPC2_interrupt_s1_s  IRQ_TYPE_LEVEL_HIGH>;
		qos = <15>;

		sysmmu,secure-irq;
		sysmmu,secure_base = <0x166C0000>;
		sysmmu,default_tlb = <TLB_CFG(BL1, PREFETCH_NONE)>;
		sysmmu,tlb_property =
			<1 TLB_CFG(BL1, PREFETCH_PREDICTION) DIR_READ  SYSMMU_ID_MASK(0x0,  0x37)>,
			<2 TLB_CFG(BL1, PREFETCH_PREDICTION) DIR_READ  SYSMMU_ID_MASK(0x1,  0x37)>,
			<3 TLB_CFG(BL1, PREFETCH_PREDICTION) DIR_READ  SYSMMU_ID_MASK(0x2,  0x37)>,
			<4 TLB_CFG(BL1, PREFETCH_PREDICTION) DIR_RW    SYSMMU_ID_MASK(0x10, 0x37)>,
			<5 TLB_CFG(BL1, PREFETCH_PREDICTION) DIR_RW    SYSMMU_ID_MASK(0x11, 0x37)>,
			<6 TLB_CFG(BL1, PREFETCH_PREDICTION) DIR_RW    SYSMMU_ID_MASK(0x12, 0x37)>,
			<7 TLB_CFG(BL1, PREFETCH_PREDICTION) DIR_WRITE SYSMMU_ID_MASK(0x20, 0x20)>;
		port-name = "VPC M2";
		#iommu-cells = <0>;
		clocks = <&clock GATE_SYSMMU_VPC2_QCH_S1>;
		clock-names = "aclk";
		power-domains = <&pd_vpc>;
	};
};
